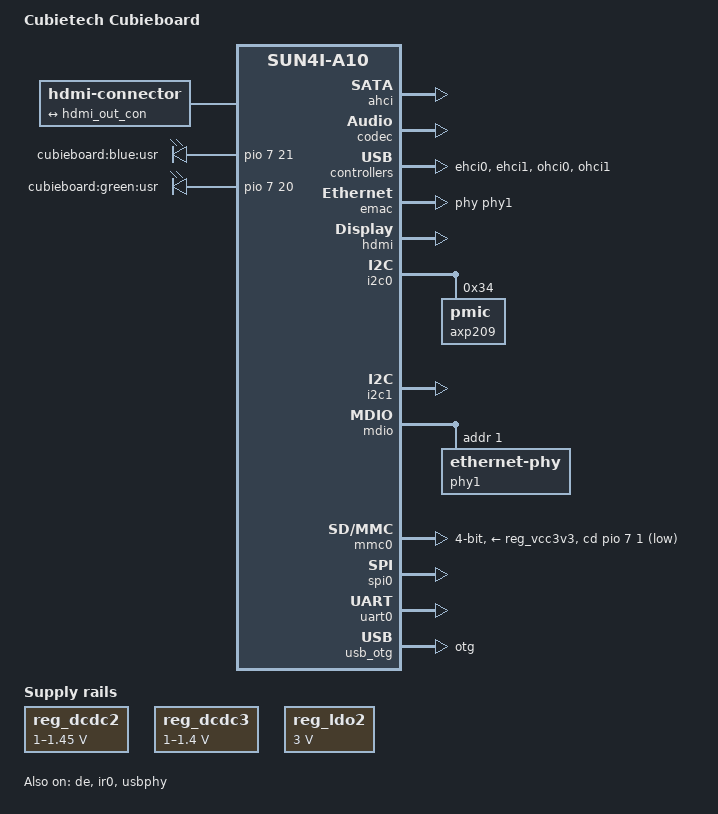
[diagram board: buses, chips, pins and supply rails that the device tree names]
/dts-v1/;
#include "sun4i-a10.dtsi"
#include "sunxi-common-regulators.dtsi"
#include <dt-bindings/gpio/gpio.h>
/ {
	model = "Cubietech Cubieboard";
	compatible = "cubietech,a10-cubieboard", "allwinner,sun4i-a10";
	aliases {
		serial0 = &uart0;
	};
	chosen {
		stdout-path = "serial0:115200n8";
	};
	hdmi-connector {
		compatible = "hdmi-connector";
		type = "a";
		port {
			hdmi_con_in: endpoint {
				remote-endpoint = <&hdmi_out_con>;
			};
		};
	};
	leds {
		compatible = "gpio-leds";
		pinctrl-names = "default";
		pinctrl-0 = <&led_pins_cubieboard>;
		led-0 {
			label = "cubieboard:blue:usr";
			gpios = <&pio 7 21 GPIO_ACTIVE_HIGH>;  
		};
		led-1 {
			label = "cubieboard:green:usr";
			gpios = <&pio 7 20 GPIO_ACTIVE_HIGH>;  
			linux,default-trigger = "heartbeat";
		};
	};
};
&ahci {
	target-supply = <&reg_ahci_5v>;
	status = "okay";
};
&codec {
	status = "okay";
};
&cpu0 {
	cpu-supply = <&reg_dcdc2>;
};
&de {
	status = "okay";
};
&ehci0 {
	status = "okay";
};
&ehci1 {
	status = "okay";
};
&emac {
	phy-handle = <&phy1>;
	status = "okay";
};
&emac_sram {
	status = "okay";
};
&hdmi {
	status = "okay";
};
&hdmi_out {
	hdmi_out_con: endpoint {
		remote-endpoint = <&hdmi_con_in>;
	};
};
&i2c0 {
	status = "okay";
	axp209: pmic@34 {
		reg = <0x34>;
		interrupts = <0>;
	};
};
&i2c1 {
	status = "okay";
};
&ir0 {
	pinctrl-names = "default";
	pinctrl-0 = <&ir0_rx_pins>;
	status = "okay";
};
&mdio {
	status = "okay";
	phy1: ethernet-phy@1 {
		reg = <1>;
	};
};
&mmc0 {
	vmmc-supply = <&reg_vcc3v3>;
	bus-width = <4>;
	cd-gpios = <&pio 7 1 GPIO_ACTIVE_LOW>;  
	status = "okay";
};
&ohci0 {
	status = "okay";
};
&ohci1 {
	status = "okay";
};
&otg_sram {
	status = "okay";
};
&pio {
	led_pins_cubieboard: led-pins {
		pins = "PH20", "PH21";
		function = "gpio_out";
		drive-strength = <20>;
	};
};
&reg_ahci_5v {
	status = "okay";
};
#include "axp209.dtsi"
&ac_power_supply {
	status = "okay";
};
&reg_dcdc2 {
	regulator-always-on;
	regulator-min-microvolt = <1000000>;
	regulator-max-microvolt = <1450000>;
	regulator-name = "vdd-cpu";
};
&reg_dcdc3 {
	regulator-always-on;
	regulator-min-microvolt = <1000000>;
	regulator-max-microvolt = <1400000>;
	regulator-name = "vdd-int-dll";
};
&reg_ldo1 {
	regulator-name = "vdd-rtc";
};
&reg_ldo2 {
	regulator-always-on;
	regulator-min-microvolt = <3000000>;
	regulator-max-microvolt = <3000000>;
	regulator-name = "avcc";
};
&reg_usb1_vbus {
	status = "okay";
};
&reg_usb2_vbus {
	status = "okay";
};
&spi0 {
	pinctrl-names = "default";
	pinctrl-0 = <&spi0_pi_pins>,
		    <&spi0_cs0_pi_pin>;
	status = "okay";
};
&uart0 {
	pinctrl-names = "default";
	pinctrl-0 = <&uart0_pb_pins>;
	status = "okay";
};
&usb_otg {
	dr_mode = "otg";
	status = "okay";
};
&usbphy {
	usb0_id_det-gpios = <&pio 7 4 (GPIO_ACTIVE_HIGH | GPIO_PULL_UP)>;  
	usb1_vbus-supply = <&reg_usb1_vbus>;
	usb2_vbus-supply = <&reg_usb2_vbus>;
	status = "okay";
};
